# STM32N645 register map
File version: 1.0
CPU: CM55 r0p1, little endian, no MPU, FPU, vendor SysTick, 8 interrupt priority bits
Registers are 32-bit, read-write, reset 0x0 unless marked. A register's access mark holds for its fields unless they carry their own. Offsets are from the block's base; [hi:lo] are bit positions; {n}, {i} and the like mark numbered series.

## PWR — Power control
Base 0x46024800
Same registers: PWR_S 0x56024800
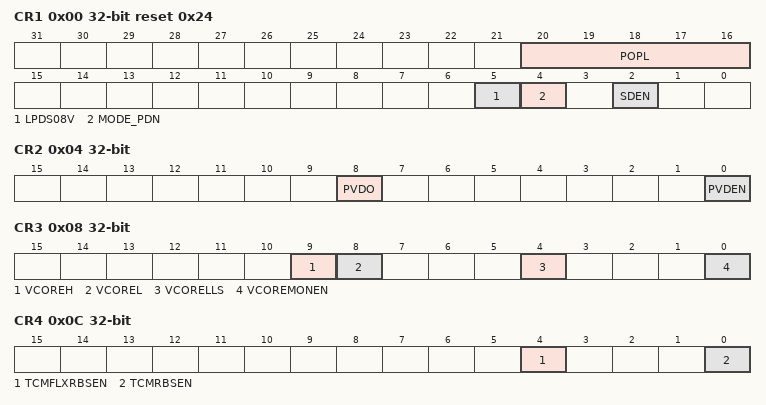
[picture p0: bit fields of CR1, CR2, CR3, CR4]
0x00 CR1 access per field reset 0x24 — PWR control register 1
  [20:16] POPL rw — pwr_on pulse low configuration.
  [5] LPDS08V rw — SMPS low-power mode enable (SVOS high only)
  [4] MODE_PDN rw — Enables the pull down on output voltage during power-down mode
  [2] SDEN rw-once — SMPS step-down converter enable
0x04 CR2 access per field — PWR control register 2
  [8] PVDO ro — Programmable voltage detect output
  [0] PVDEN rw — Programmable voltage detector enable
0x08 CR3 access per field — PWR control register 3
  [9] VCOREH ro — Monitored V less than sub>DDCORE less than /sub> level above high threshold
  [8] VCOREL ro — Monitored V less than sub>DDCORE less than /sub> level above low threshold
  [4] VCORELLS rw — V less than sub>DDCORE less than /sub> voltage detector low-level selection
  [0] VCOREMONEN rw — V less than sub>DDCORE less than /sub> monitoring enable
0x0C CR4 — PWR control register 4
  [4] TCMFLXRBSEN — I-TCM FLEXMEM backup supply enable (used to maintain I-TCM FLEX MEM content in Standby mode)
  [0] TCMRBSEN — I-TCM and D-TCM RAMs backup supply enable (used to maintain TCM RAMs content in Standby mode)
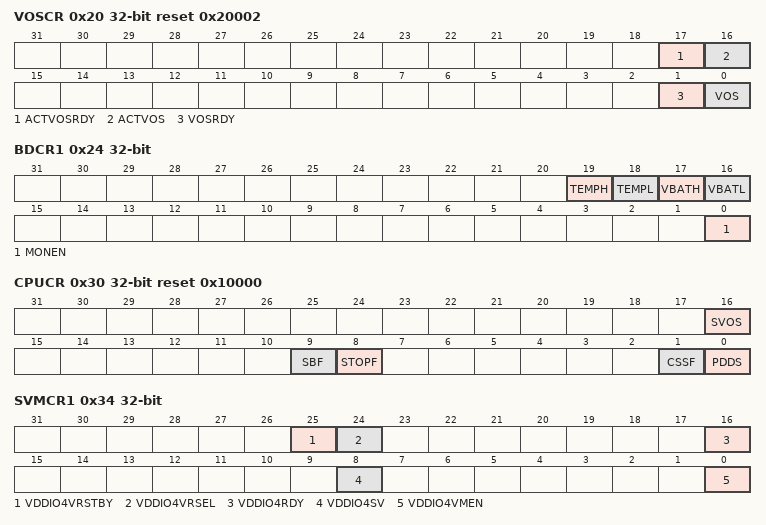
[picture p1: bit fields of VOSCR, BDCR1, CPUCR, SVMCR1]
0x20 VOSCR access per field reset 0x20002 — PWR voltage scaling control register
  [17] ACTVOSRDY ro — Voltage level ready bit for currently used ACTVOS
  [16] ACTVOS ro — VOS currently applied for V less than sub>CORE less than /sub> voltage scaling selection
  [1] VOSRDY ro — VOS ready bit for V less than sub>CORE less than /sub> voltage scaling output selection
  [0] VOS rw — Voltage scaling selection according to performance
0x24 BDCR1 access per field — PWR backup domain control register 1
  [19] TEMPH ro — Temperature level monitoring versus high threshold
  [18] TEMPL ro — Temperature level monitoring versus low threshold
  [17] VBATH ro — V less than sub>BAT less than /sub> level monitoring versus high threshold
  [16] VBATL ro — V less than sub>BAT less than /sub> level monitoring versus low threshold
  [0] MONEN rw — V less than sub>BAT less than /sub> and temperature monitoring enable
0x28 BDCR2 — PWR backup domain control register 2
  [0] BKPRBSEN — Backup RAM backup supply enable (used to maintain BKPRAM content in Standby and V less than sub>BAT less than /sub> modes).
0x2C DBPCR — PWR disable backup protection control register
  [0] DBP — Disable backup domain write protection
0x30 CPUCR access per field reset 0x10000 — PWR CPU control register
  [16] SVOS rw — System Stop mode voltage scaling selection
  [9] SBF ro — Standby flag
  [8] STOPF ro — Stop flag
  [1] CSSF rw — Clear Standby and Stop flags (always read as 0)
  [0] PDDS rw — Power-down deepsleep selection
0x34 SVMCR1 access per field — PWR supply voltage monitoring control register 1
  [25] VDDIO4VRSTBY rw — V less than sub>DDIO4 less than /sub> I/O voltage range Standby mode
  [24] VDDIO4VRSEL rw — V less than sub>DDIO4 less than /sub> I/O voltage range selection
  [16] VDDIO4RDY ro — V less than sub>DDIO4 less than /sub>ready
  [8] VDDIO4SV rw — V less than sub>DDIO4 less than /sub>independent I/O supply valid.
  [0] VDDIO4VMEN rw — V less than sub>DDIO4 less than /sub>independent I/O voltage monitor enable
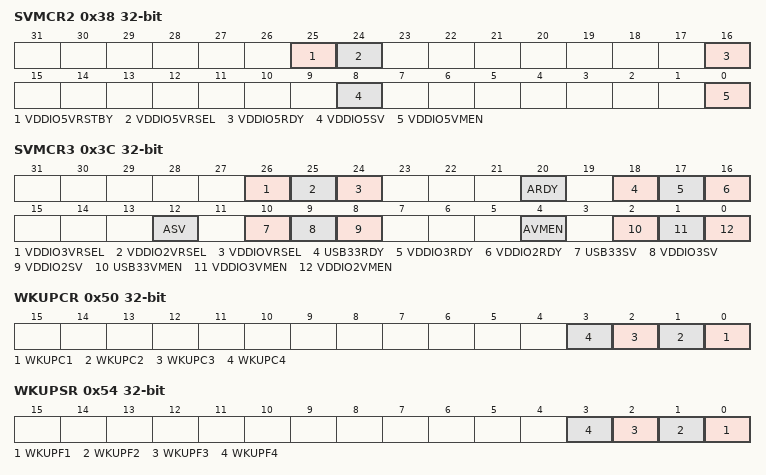
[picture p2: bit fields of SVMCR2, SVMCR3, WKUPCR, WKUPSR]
0x38 SVMCR2 access per field — PWR supply voltage monitoring control register 2
  [25] VDDIO5VRSTBY rw — V less than sub>DDIO5 less than /sub> I/O voltage range Standby mode
  [24] VDDIO5VRSEL rw — V less than sub>DDIO5 less than /sub> I/O voltage range selection
  [16] VDDIO5RDY ro — V less than sub>DDIO5 less than /sub>ready
  [8] VDDIO5SV rw — V less than sub>DDIO5 less than /sub>independent supply valid
  [0] VDDIO5VMEN rw — V less than sub>DDIO5 less than /sub>independent voltage monitor enable
0x3C SVMCR3 access per field — PWR supply voltage monitoring control register 3
  [26] VDDIO3VRSEL rw — V less than sub>DDIO3 less than /sub> I/O voltage range selection
  [25] VDDIO2VRSEL rw — V less than sub>DDIO2 less than /sub> I/O voltage range selection
  [24] VDDIOVRSEL rw — V less than sub>DD less than /sub> I/O voltage range selection
  [20] ARDY ro — V less than sub>DDA18ADC less than /sub>ready
  [18] USB33RDY ro — V less than sub>DD33USB less than /sub>ready
  [17] VDDIO3RDY ro — V less than sub>DDIO3 less than /sub>ready
  [16] VDDIO2RDY ro — V less than sub>DDIO2 less than /sub>ready
  [12] ASV rw — V less than sub>DDA18ADC less than /sub>independent supply valid
  [10] USB33SV rw — V less than sub>DD33USB less than /sub>independent supply valid
  [9] VDDIO3SV rw — V less than sub>DDIO3 less than /sub>independent supply valid
  [8] VDDIO2SV rw — V less than sub>DDIO2 less than /sub>independent supply valid.
  [4] AVMEN rw — V less than sub>DDA18ADC less than /sub>independent ADC voltage monitor enable
  [2] USB33VMEN rw — V less than sub>DD33USB less than /sub>independent USB 33 voltage monitor enable.
  [1] VDDIO3VMEN rw — V less than sub>DDIO3 less than /sub>independent voltage monitor enable
  [0] VDDIO2VMEN rw — V less than sub>DDIO2 less than /sub>independent voltage monitor enable
0x50 WKUPCR wo — PWR wake-up clear register
  [n-1] WKUPC{n} (n=1..4) — Clear wake-up flag for WKUP{n} pin
0x54 WKUPSR ro — PWR wake-up status register
  [n-1] WKUPF{n} (n=1..4) — Wake-up flag for WKUP{n} pin before enable
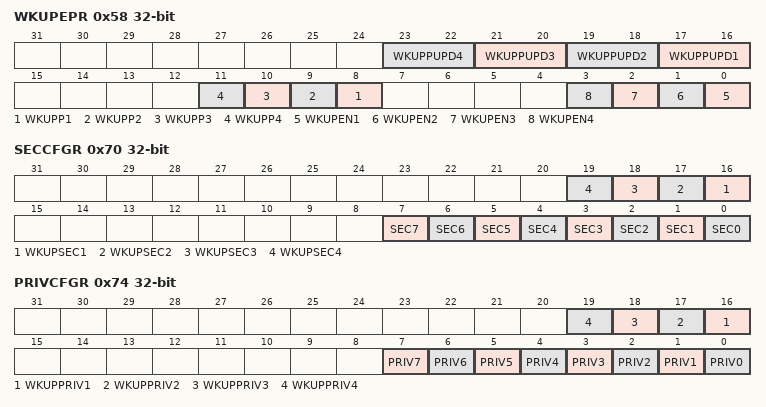
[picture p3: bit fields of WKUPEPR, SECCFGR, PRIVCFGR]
0x58 WKUPEPR — PWR wake-up enable and polarity register
  [2n+15:2n+14] WKUPPUPD{n} (n=1..4) — Wake-up pull configuration for WKUP{n} pin
  [n+7] WKUPP{n} (n=1..4) — Wake-up polarity bit for WKUP{n} pin
  [n-1] WKUPEN{n} (n=1..4) — Enable WKUP{n} pin
0x70 SECCFGR — PWR security configuration register
  [n+15] WKUPSEC{n} (n=1..4) — WKUP{n} pin secure protection
  [7] SEC7 — Peripheral voltage monitor secure protection
  [6] SEC6 — CPU power control secure protection
  [5] SEC5 — Backup domain secure protection
  [4] SEC4 — Voltage scaling selection secure protection
  [3] SEC3 — I-TCM, D-TCM, and I-TCM FLEXMEM low power control secure protection
  [2] SEC2 — V less than sub>DDCORE less than /sub> monitor secure protection
  [1] SEC1 — Programmable voltage detector secure protection
  [0] SEC0 — System supply configuration secure protection
0x74 PRIVCFGR — PWR privilege configuration register
  [n+15] WKUPPRIV{n} (n=1..4) — WKUP{n} pin privileged protection
  [7] PRIV7 — Peripheral voltage monitor privileged protection
  [6] PRIV6 — CPU power control privileged protection
  [5] PRIV5 — Backup domain privileged protection
  [4] PRIV4 — Voltage scaling selection privileged protection
  [3] PRIV3 — I-TCM, D-TCM, and I-TCM FLEX MEM low power control privileged protection
  [2] PRIV2 — V less than sub>DDCORE less than /sub> monitor privileged protection
  [1] PRIV1 — Programmable voltage detector privileged protection
  [0] PRIV0 — System supply configuration privileged protection
